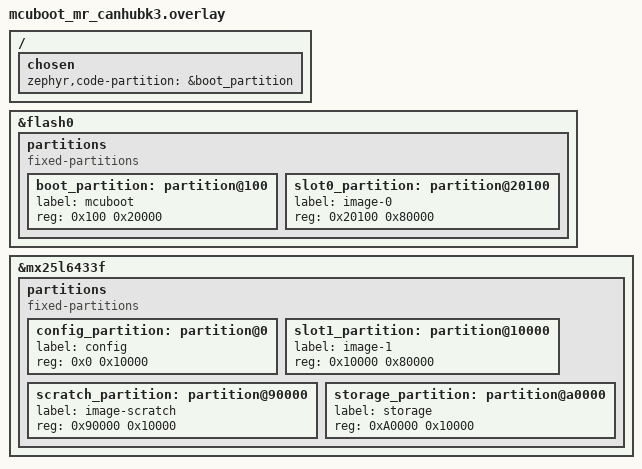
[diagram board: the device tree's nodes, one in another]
/* MCUboot DTS overlay for MR-CANHUBK3
 * Must mirror the partition layout from the app overlay.
 * MCUboot runs from boot_partition and needs to know slot0/slot1/scratch.
 */

&flash0 {
	partitions {
		compatible = "fixed-partitions";
		#address-cells = <1>;
		#size-cells = <1>;

		/delete-node/ partition@100;

		boot_partition: partition@100 {
			label = "mcuboot";
			reg = <0x100 0x20000>;
		};

		slot0_partition: partition@20100 {
			label = "image-0";
			reg = <0x20100 0x80000>;
		};
	};
};

&mx25l6433f {
	partitions {
		compatible = "fixed-partitions";
		#address-cells = <1>;
		#size-cells = <1>;

		/delete-node/ partition@0;

		config_partition: partition@0 {
			label = "config";
			reg = <0x0 0x10000>;
		};

		slot1_partition: partition@10000 {
			label = "image-1";
			reg = <0x10000 0x80000>;
		};

		scratch_partition: partition@90000 {
			label = "image-scratch";
			reg = <0x90000 0x10000>;
		};

		storage_partition: partition@a0000 {
			label = "storage";
			reg = <0xA0000 0x10000>;
		};
	};
};

/ {
	chosen {
		zephyr,code-partition = &boot_partition;
	};
};
